# AC78xx register map
Vendor: AutoChips; Series: AC78xx; File version: 1.0
CPU: CM3 r2p1, little endian, MPU, no FPU, 3 interrupt priority bits
Registers are 32-bit, read-write, no defined reset value unless marked. A register's access mark holds for its fields unless they carry their own. Offsets are from the block's base; [hi:lo] are bit positions.

## UART1
Base 0x40018000; register names take the prefix UART1_
0x00 RBR — RX/TX Data Register
  [7:0] RBR_THR
0x04 DIV_L — Divisor low 8 bits register
  [7:0] DIV_L — uart baud rate divisor low 8 bits
0x08 DIV_H — Divisor high 8 bits register
  [7:0] DIV_H — uart baud rate divisor high 8 bits
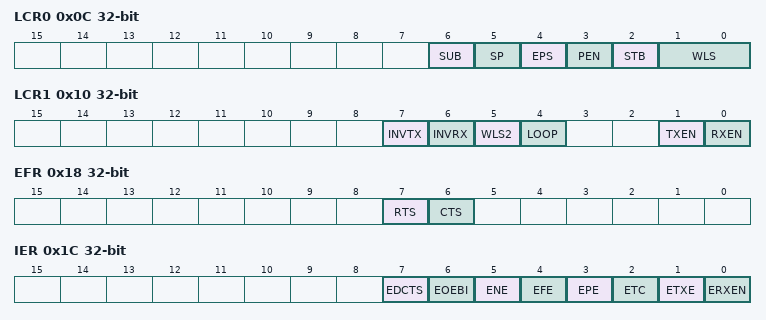
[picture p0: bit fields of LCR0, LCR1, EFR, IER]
0x0C LCR0 — uart control register 0
  [6] SUB — Sets up break
  [5] SP — stick parity
  [4] EPS — odd/eveen number select bit
  [3] PEN — uart parity enable/disable bit
  [2] STB — Number of STOP bits
  [1:0] WLS — uart data mode select bits
0x10 LCR1 — uart control register 1
  [7] INVTX — uart tx output inverse enable/disable bit
  [6] INVRX — uart rx input inverse enable/disable bit
  [5] WLS2 — uart 9 bit data mode enable/disable bit
  [4] LOOP — uart loop back mode enable
  [1] TXEN — uart Transmitter enable
  [0] RXEN — uart receiver enable
0x14 FCR — FIFO Control Register
  [0] FIFOE — RX and TX FIFO enable/disable bit
0x18 EFR — hardware flow control register
  [7] RTS — hardware reception flow control enable/disable bit
  [6] CTS — hardware transmiison flow control enable/disable bit
0x1C IER — Interrupt Enable register
  [7] EDCTS — CTS_n changing interrupt enable bit
  [6] EOEBI — overflow error or break error interrupt enable bit
  [5] ENE — noise error interrupt enable bit
  [4] EFE — overflow or frame error interrupt enable bit
  [3] EPE — parity error interrupt enable bit
  [2] ETC — transmitting completed interrupt enable bit
  [1] ETXE — transmitting data empty interrupt enable bit
  [0] ERXEN — receiving data not empty interrupt enable bit
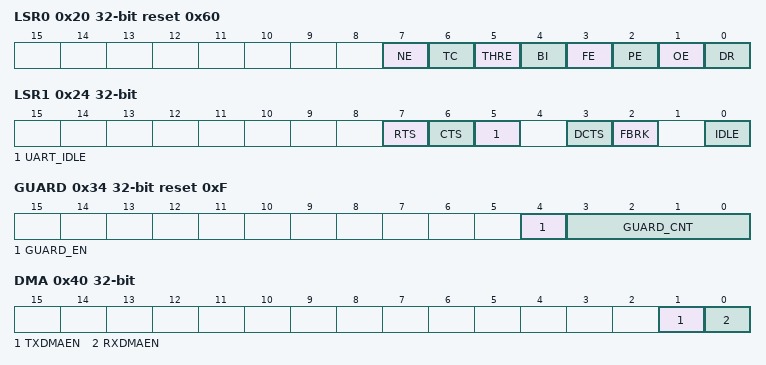
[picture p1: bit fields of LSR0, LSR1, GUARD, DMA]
0x20 LSR0 reset 0x60 (reset mask 0x0) — Line Status Register 0
  [7] NE — noise error flag
  [6] TC — Transmitting finished flag
  [5] THRE — the empty flag of TX holding register or TX FIFO
  [4] BI — break error flag
  [3] FE — frame error flag
  [2] PE — parity error flag
  [1] OE — overrun error flag
  [0] DR — Data ready flag
0x24 LSR1 — Line Status Register 1
  [7] RTS — Hardware flow status - RTS
  [6] CTS — Hardware flow status - CTS
  [5] UART_IDLE
  [3] DCTS — flag of pin CTS_n signal changing
  [2] FBRK — LIN break occurrer flag
  [0] IDLE — IDLE flag
0x28 SMP_CNT — uart sample counter register
  [1:0] SMP_CNT — uart sample counter
0x34 GUARD reset 0xF (reset mask 0x0) — uart guard time register
  [4] GUARD_EN — Guard interval time added enabling signal
  [3:0] GUARD_CNT — Guard interval count value
0x3C SLEEP — uart sleep enable register
  [0] SLEEP_EN — uart sleep function enable bit
0x40 DMA — uart DMA enable register
  [1] TXDMAEN — uart TX DMA enable bit
  [0] RXDMAEN — uart RX DMA enable bit
0x44 DIV_FRAC — Uart Fractional Divider Address
  [7:0] DIV_FRAC — uart fractional divider
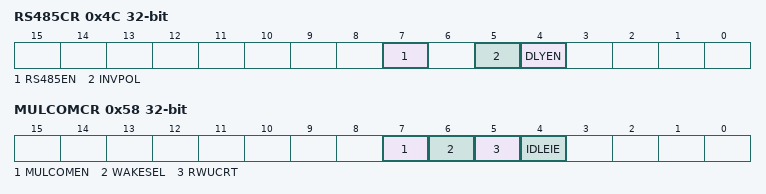
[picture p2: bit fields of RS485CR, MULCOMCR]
0x4C RS485CR — Uart RS485 control register
  [7] RS485EN — RS485 mode enable bit
  [5] INVPOL — inverse the polarity of rts_n
  [4] DLYEN — Delay insert between the last stop bit and rts_n or dtr_n de-assertion
0x50 SLADDR — Uart address for wake up
  [7:0] SLADDR — slave address for RS485
0x54 CNTR — Uart Counter time delay in RS485 mode
  [7:0] CNTR
0x58 MULCOMCR — Uart multiprocessor communication control register
  [7] MULCOMEN — Multi communication enable bit
  [6] WAKESEL — Wakeup method select
  [5] RWUCRT — Receiver wakeup control
  [4] IDLEIE — IDLE interrupt enable bit

## UART2
Base 0x40019000; register names take the prefix UART2_
Registers as UART1.

## UART3
Base 0x4001A000; register names take the prefix UART3_
Registers as UART1.

## UART4
Base 0x4001B000; register names take the prefix UART4_
Registers as UART1.

## UART5
Base 0x4001C000; register names take the prefix UART5_
Registers as UART1.

## UART6
Base 0x4001D000; register names take the prefix UART6_
Registers as UART1; these are added or differ:
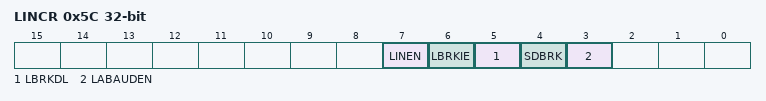
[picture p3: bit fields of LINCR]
0x5C LINCR — Uart Lin control register
  [7] LINEN — LIN Mode enable bit
  [6] LBRKIE — LIN Break character detect interrupt enable bit
  [5] LBRKDL — LIN Mode break detect length
  [4] SDBRK — LIN Mode whether transmit enable bit
  [3] LABAUDEN — 0x55 used to auto baud-rate detection enable bit
